# STM32MP21_CA35 register map
File version: 0.4
CPU: CM33 r0p1, little endian, MPU, FPU, vendor SysTick, 8 interrupt priority bits
Registers are 32-bit, read-write, reset 0x0 unless marked. A register's access mark holds for its fields unless they carry their own. Offsets are from the block's base; [hi:lo] are bit positions; {n}, {i} and the like mark numbered series; 'fields as' and 'values as' point back to an identical list.

## EXTI2 — EXTI2 address block description
Base 0x442D0000
Same registers: EXTI2_S 0x542D0000
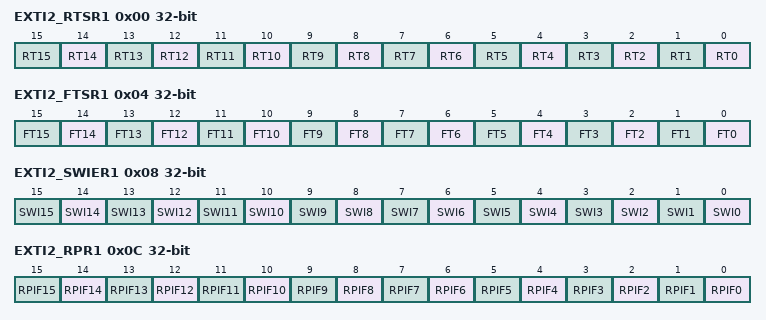
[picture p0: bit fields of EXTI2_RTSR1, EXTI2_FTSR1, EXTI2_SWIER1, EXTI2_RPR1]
0x00 EXTI2_RTSR1 — EXTI2 rising trigger selection register
  [all] fields
    0=Rising trigger disabled (for event and interrupt) for input line x; 1=Rising trigger enabled (for event and interrupt) for input line x
  [n] RT{n} (n=0..15) — Rising trigger event configuration bit of configurable event input x
0x04 EXTI2_FTSR1 — EXTI2 falling trigger selection register
  [all] fields
    0=Falling trigger disabled (for event and Interrupt) for input line x; 1=Falling trigger enabled (for event and Interrupt) for input line x
  [n] FT{n} (n=0..15) — Falling trigger event configuration bit of configurable event input x
0x08 EXTI2_SWIER1 — EXTI2 software interrupt event register
  [all] fields
    0=Writing 0 has no effect; 1=Writing 1 to this bit triggers a rising edge event on event x (bit auto cleared by hardware)
  [n] SWI{n} (n=0..15) — Software interrupt on event x
0x0C EXTI2_RPR1 — EXTI2 rising edge pending register
  [all] fields
    0=No rising edge trigger request occurred; 1=Rising edge trigger request occurred
  [n] RPIF{n} (n=0..15) — Configurable event input x rising edge pending bit
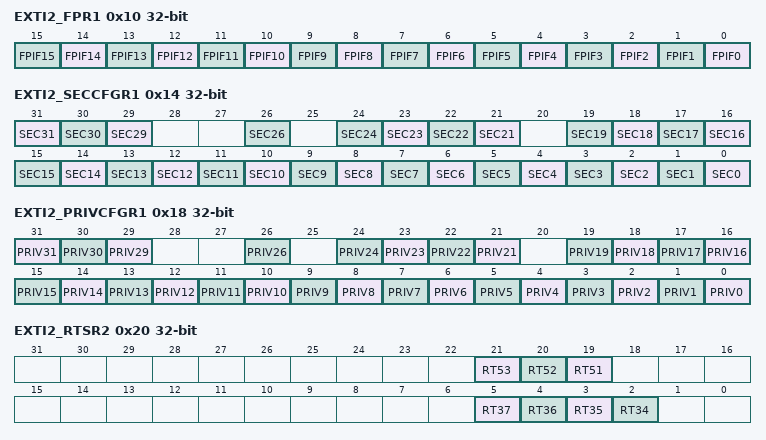
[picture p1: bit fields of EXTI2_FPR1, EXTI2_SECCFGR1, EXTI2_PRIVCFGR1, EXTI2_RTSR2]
0x10 EXTI2_FPR1 — EXTI2 falling edge pending register
  [all] fields
    0=No falling edge trigger request occurred; 1=Falling edge trigger request occurred
  [n] FPIF{n} (n=0..15) — Configurable event input x falling edge pending bit
0x14 EXTI2_SECCFGR1 — EXTI2 security configuration register
  [31] SEC31 — Security enable on event input x
    0=Event security disabled (non-secure); 1=Event security enabled (secure)
  [30] SEC30 — Security enable on event input x
    values as SEC31
  [29] SEC29 — Security enable on event input x
    values as SEC31
  [26] SEC26 — Security enable on event input 26
  [n] SEC{n} (n=21..24) — Security enable on event input x
  [n] SEC{n} (n=0..19) — Security enable on event input x
0x18 EXTI2_PRIVCFGR1 — EXTI2 privilege configuration register
  [31] PRIV31 — Privilege enable on event input x
    0=Event privilege disabled (unprivileged); 1=Event privilege enabled (privileged)
  [30] PRIV30 — Privilege enable on event input x
    values as PRIV31
  [29] PRIV29 — Privilege enable on event input x
    values as PRIV31
  [26] PRIV26 — Privilege enable on event input 26
  [n] PRIV{n} (n=21..24) — Privilege enable on event input x
  [n] PRIV{n} (n=0..19) — Privilege enable on event input x
0x20 EXTI2_RTSR2 — EXTI2 rising trigger selection register
  [21] RT53 — Rising trigger event configuration bit of configurable event input x
    values as the fields of EXTI2_RTSR1
  [20] RT52 — Rising trigger event configuration bit of configurable event input x
    values as the fields of EXTI2_RTSR1
  [19] RT51 — Rising trigger event configuration bit of configurable event input x
    values as the fields of EXTI2_RTSR1
  [n-32] RT{n} (n=34..37) — Rising trigger event configuration bit of configurable event input x
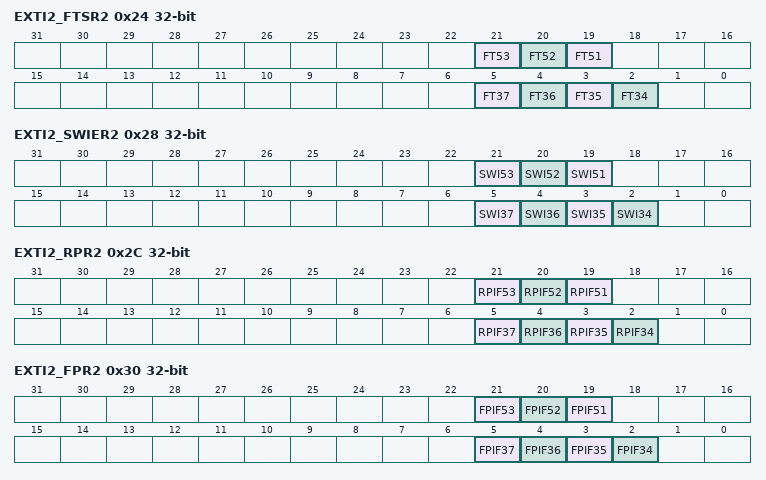
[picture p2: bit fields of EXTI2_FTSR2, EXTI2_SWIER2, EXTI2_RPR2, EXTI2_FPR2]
0x24 EXTI2_FTSR2 — EXTI2 falling trigger selection register
  [21] FT53 — Falling trigger event configuration bit of configurable event input x
    0=Falling trigger disabled (for event and interrupt) for input line x; 1=Falling trigger enabled (for event and interrupt) for input line x
  [20] FT52 — Falling trigger event configuration bit of configurable event input x
    values as FT53
  [19] FT51 — Falling trigger event configuration bit of configurable event input x
    values as FT53
  [n-32] FT{n} (n=34..37) — Falling trigger event configuration bit of configurable event input x
0x28 EXTI2_SWIER2 — EXTI2 software interrupt event register
  [21] SWI53 — Software interrupt on event x
    values as the fields of EXTI2_SWIER1
  [20] SWI52 — Software interrupt on event x
    values as the fields of EXTI2_SWIER1
  [19] SWI51 — Software interrupt on event x
    values as the fields of EXTI2_SWIER1
  [n-32] SWI{n} (n=34..37) — Software interrupt on event x
0x2C EXTI2_RPR2 — EXTI2 rising edge pending register
  [21] RPIF53 — Configurable event input x rising edge pending bit
    values as the fields of EXTI2_RPR1
  [20] RPIF52 — Configurable event input x rising edge pending bit
    values as the fields of EXTI2_RPR1
  [19] RPIF51 — Configurable event input x rising edge pending bit
    values as the fields of EXTI2_RPR1
  [n-32] RPIF{n} (n=34..37) — Configurable event input x rising edge pending bit
0x30 EXTI2_FPR2 — EXTI2 falling edge pending register
  [21] FPIF53 — Configurable event input x pending bit
    values as the fields of EXTI2_FPR1
  [20] FPIF52 — Configurable event input x pending bit
    values as the fields of EXTI2_FPR1
  [19] FPIF51 — Configurable event input x pending bit
    values as the fields of EXTI2_FPR1
  [n-32] FPIF{n} (n=34..37) — Configurable event input x pending bit
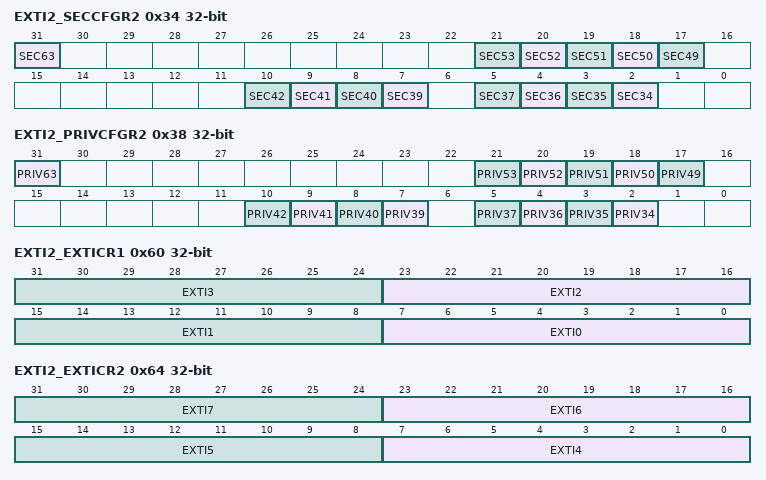
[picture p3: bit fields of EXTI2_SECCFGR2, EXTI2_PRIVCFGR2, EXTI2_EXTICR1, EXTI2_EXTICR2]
0x34 EXTI2_SECCFGR2 — EXTI2 security enable register
  [31] SEC63 — Security enable on event input 63
    values as EXTI2_SECCFGR1.SEC31
  [n-32] SEC{n} (n=49..53) — Security enable on event input x
  [n-32] SEC{n} (n=39..42) — Security enable on event input x
  [n-32] SEC{n} (n=34..37) — Security enable on event input x
0x38 EXTI2_PRIVCFGR2 — EXTI2 privilege enable register
  [31] PRIV63 — Privilege enable on event input 63
    values as EXTI2_PRIVCFGR1.PRIV31
  [n-32] PRIV{n} (n=49..53) — Privilege enable on event input x
  [n-32] PRIV{n} (n=39..42) — Privilege enable on event input x
  [n-32] PRIV{n} (n=34..37) — Privilege enable on event input x
0x60 EXTI2_EXTICR1 — EXTI2 external interrupt selection register 1
  [8n+7:8n] EXTI{n} (n=0..3) — EXTI{n} GPIO port selection
    0=PA{n} pin; 1=PB{n} pin; 2=PC{n} pin; 3=PD{n} pin; 4=PE{n} pin; 5=PF{n} pin; 6=PG{n} pin; 7=PH{n} pin; 8=PI{n} pin; 9=PZ{n} pin
0x64 EXTI2_EXTICR2 — EXTI2 external interrupt selection register 2
  [8n-25:8n-32] EXTI{n} (n=4..7) — EXTI{n} GPIO port selection
    values as EXTI2_EXTICR1.EXTI0
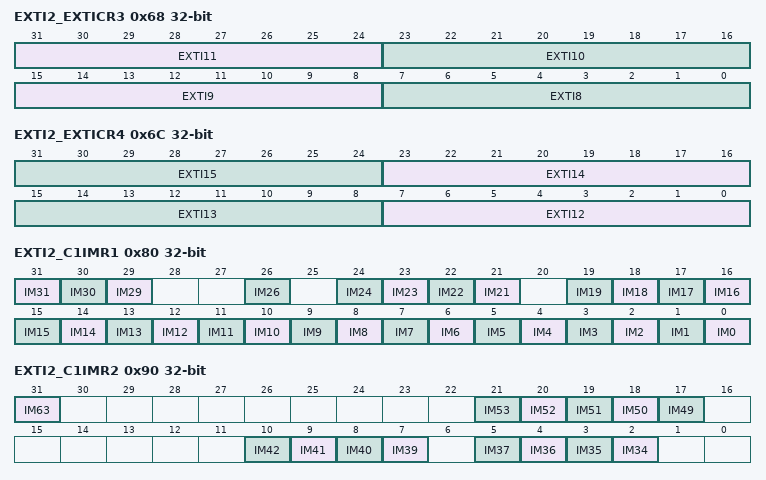
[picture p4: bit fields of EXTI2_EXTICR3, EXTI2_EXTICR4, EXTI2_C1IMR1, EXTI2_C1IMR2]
0x68 EXTI2_EXTICR3 — EXTI2 external interrupt selection register 3
  [31:24] EXTI11 — EXTI11 GPIO port selection
    0=PA11 pin; 1=PB11 pin; 2=PC11 pin; 3=PD11 pin; 4=PE11 pin; 5=PF11 pin; 6=PG11 pin; 7=PH11 pin; 8=PI11 pin; 9=PZ11 pin
  [23:16] EXTI10 — EXTI10 GPIO port selection
    0=PA10 pin; 1=PB10 pin; 2=PC10 pin; 3=PD10 pin; 4=PE10 pin; 5=PF10 pin; 6=PG10 pin; 7=PH10 pin; 8=PI10 pin; 9=PZ10 pin
  [15:8] EXTI9 — EXTI9 GPIO port selection
    0=PA9 pin; 1=PB9 pin; 2=PC9 pin; 3=PD9 pin; 4=PE9 pin; 5=PF9 pin; 6=PG9 pin; 7=PH9 pin; 8=PI9 pin; 9=PZ9 pin
  [7:0] EXTI8 — EXTI9 GPIO port selection
    0=PA8 pin; 1=PB8 pin; 2=PC8 pin; 3=PD8 pin; 4=PE8 pin; 5=PF8 pin; 6=PG8 pin; 7=PH8 pin; 8=PI8 pin; 9=PZ8 pin
0x6C EXTI2_EXTICR4 — EXTI2 external interrupt selection register 4
  [8n-89:8n-96] EXTI{n} (n=12..15) — EXTI{n} GPIO port selection
    values as EXTI2_EXTICR1.EXTI0
0x70 EXTI2_LOCKR — EXTI2 lock register
  [0] GLOCK — Global security, privilege and CID configuration registers EXTI2_SECCFGRx, EXTI2_PRIVCFGRx, EXTI2_EnCIDCFGR and EXTI2_CmCIDCFGR lock
    0=Security and privilege configuration open, can be modified; 1=Security and privilege configuration locked, can no longer be modified
0x80 EXTI2_C1IMR1 — EXTI2 CPU1 wake-up with interrupt mask register
  [31] IM31 — CPUm wake-up with interrupt mask on event input x
    0=Wake-up and interrupt CPU(m) from input event x is masked; 1=Wake-up and interrupt CPU(m) from input event x is unmasked
  [30] IM30 — CPUm wake-up with interrupt mask on event input x
    values as IM31
  [29] IM29 — CPUm wake-up with interrupt mask on event input x
    values as IM31
  [26] IM26 — CPUm wake-up with interrupt mask on event input 26
  [n] IM{n} (n=21..24) — CPUm wake-up with interrupt mask on event input x
  [n] IM{n} (n=0..19) — CPUm wake-up with interrupt mask on event input x
0x90 EXTI2_C1IMR2 — EXTI2 CPU1 wake-up with interrupt mask register
  [31] IM63 — CPUm wake-up with interrupt mask on event input 63
    values as EXTI2_C1IMR1.IM31
  [n-32] IM{n} (n=49..53) — CPUm wake-up with interrupt mask on event input x
  [n-32] IM{n} (n=39..42) — CPUm wake-up with interrupt mask on event input x
  [n-32] IM{n} (n=34..37) — CPUm wake-up with interrupt mask on event input x
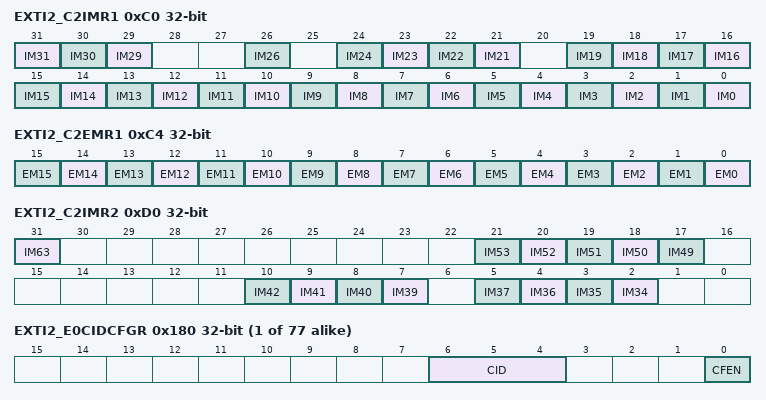
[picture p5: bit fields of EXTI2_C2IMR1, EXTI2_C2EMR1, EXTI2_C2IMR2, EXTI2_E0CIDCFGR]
0xC0 EXTI2_C2IMR1 — EXTI2 CPU2 wake-up with interrupt mask register
  fields as EXTI2_C1IMR1
0xC4 EXTI2_C2EMR1 — EXTI2 CPU2 wake-up with event mask register
  [all] fields
    0=Wake-up with event generation from line x is masked; 1=Wake-up with event generation from line x is unmasked
  [n] EM{n} (n=0..15) — CPU(m) wake-up with event generation mask on event input x
0xD0 EXTI2_C2IMR2 — EXTI2 CPU2 wake-up with interrupt mask register
  fields as EXTI2_C1IMR2
{0x180+4i} EXTI2_E{i}CIDCFGR (i=0..76) — EXTI2 event CID config register
  [6:4] CID — EXTI event n allowed CID value
  [0] CFEN — EXTI event n CID filtering enable
    0=Disable EXTI event x filtering (EXTI event x can be accessed by all CIDs); 1=Enable EXTI event x filtering (EXTI event x can only be accessed by the processor with CID = CPUm CID)
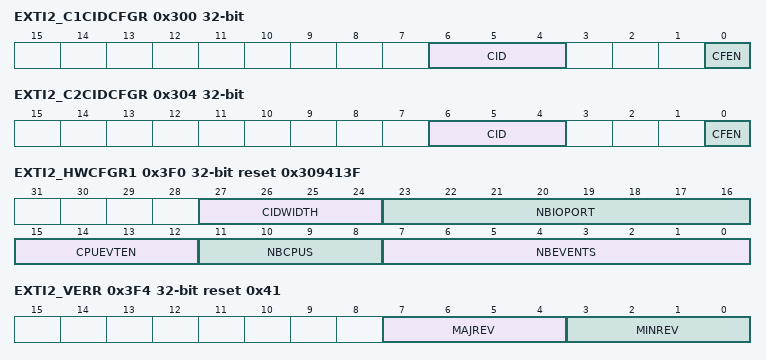
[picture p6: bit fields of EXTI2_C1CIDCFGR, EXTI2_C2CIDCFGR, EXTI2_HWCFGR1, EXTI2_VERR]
0x300 EXTI2_C1CIDCFGR — EXTI2 processor 1 CID configuration register
  [6:4] CID — CPUm CID domain identification
  [0] CFEN — CID filtering enabled for CPUm EXTI2_CmIMRn and EXTI2_CmEMRn registers
    0=Disable the CID filtering for CPUm; 1=Enable the CID filtering for CPUm
0x304 EXTI2_C2CIDCFGR — EXTI2 processor 2 CID configuration register
  fields as EXTI2_C1CIDCFGR
0x3C0 EXTI2_HWCFGR13 ro — EXTI2 hardware configuration registers 13
  [31:0] SEC — Hardware configuration event security privilege and resource isolation capability
    0=Non-secure, unprivileged and no resource filtering event; 1=Security, privilege and resource filtering capable event
0x3C4 EXTI2_HWCFGR12 ro reset 0x803E07BE — EXTI2 hardware configuration registers 12
  fields as EXTI2_HWCFGR13
0x3C8 EXTI2_HWCFGR11 ro reset 0xE5EFFFFF — EXTI2 hardware configuration registers 11
  fields as EXTI2_HWCFGR13
0x3D8 EXTI2_HWCFGR7 ro — EXTI2 hardware configuration registers 7
  [31:0] CPUEVENT — Hardware configuration CPU event generation
    0=No CPU event generated; 1=CPU event generated
0x3DC EXTI2_HWCFGR6 ro — EXTI2 hardware configuration registers 6
  fields as EXTI2_HWCFGR7
0x3E0 EXTI2_HWCFGR5 ro reset 0xFFFF — EXTI2 hardware configuration registers 5
  fields as EXTI2_HWCFGR7
0x3E4 EXTI2_HWCFGR4 ro — EXTI2 hardware configuration registers 4
  [31:0] EVENT_TRG — Hardware configuration event trigger type
    0=Direct event; 1=Configurable event
0x3E8 EXTI2_HWCFGR3 ro reset 0x38003C — EXTI2 hardware configuration registers 3
  fields as EXTI2_HWCFGR4
0x3EC EXTI2_HWCFGR2 ro reset 0xFFFF — EXTI2 hardware configuration registers 2
  fields as EXTI2_HWCFGR4
0x3F0 EXTI2_HWCFGR1 ro reset 0x309413F — EXTI2 hardware configuration register 1
  [27:24] CIDWIDTH — CID parameters bit width
  [23:16] NBIOPORT — Hardware configuration of number of I/O ports on EXTI (n+1)
  [15:12] CPUEVTEN — Hardware configuration of CPU(m) event output enable.
  [11:8] NBCPUS — Hardware configuration number of CPUs (n+1)
  [7:0] NBEVENTS — Hardware configuration number of event (n+1)
0x3F4 EXTI2_VERR ro reset 0x41 — EXTI2 version register
  [7:4] MAJREV — Major revision number
  [3:0] MINREV — Minor revision number
0x3F8 EXTI2_IPIDR ro reset 0xE0001 — EXTI2 identification register
  [31:0] IPID — EXTI2 identification
0x3FC EXTI2_SIDR ro reset 0xA3C5DD01 — EXTI2 size identification register
  [31:0] SID — Size identification
